# STM32H5F5 register map
File version: 1.0
CPU: CM33 r0p0, little endian, MPU, FPU, 4 interrupt priority bits
Registers are 32-bit, read-write, reset 0x0 unless marked. A register's access mark holds for its fields unless they carry their own. Offsets are from the block's base; [hi:lo] are bit positions; {n}, {i} and the like mark numbered series; 'fields as' and 'values as' point back to an identical list.

## AES — AES register block
Base 0x420C0000
Same registers: SAES 0x420C0C00, AES_S 0x520C0000, SAES_S 0x520C0C00
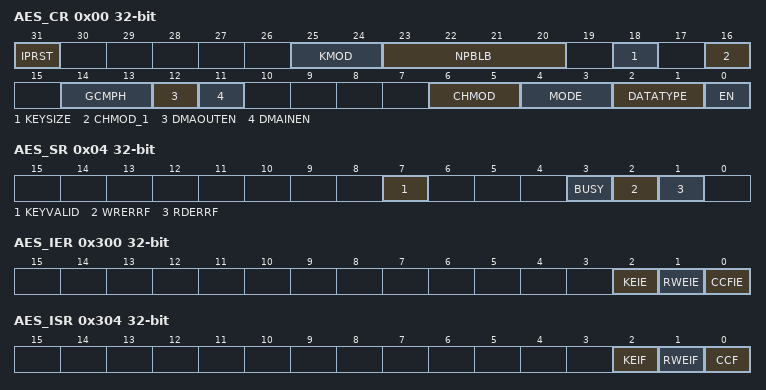
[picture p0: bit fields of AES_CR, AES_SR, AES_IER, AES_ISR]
0x00 AES_CR — AES control register
  [31] IPRST — AES peripheral software reset
  [25:24] KMOD — Key mode selection
    0=Normal key mode; 2=Shared key mode
  [23:20] NPBLB — Number of padding bytes in last block
    0=All bytes are valid (no padding); 1=Padding for the last LSB byte; 15=Padding for the 15 LSB bytes of last block
  [18] KEYSIZE — Key size selection
    0=128-bit; 1=256-bit
  [16] CHMOD_1 — CHMOD[2]
  [14:13] GCMPH — GCM or CCM phase selection
    0=Initialization phase; 1=Header phase; 2=Payload phase; 3=Final phase
  [12] DMAOUTEN — DMA output enable
    0=Disable; 1=Enable
  [11] DMAINEN — DMA input enable
    0=Disable; 1=Enable
  [6:5] CHMOD — CHMOD[1:0]: Chaining mode
    0=Electronic codebook (ECB); 1=Cipher-block chaining (CBC); 2=Counter mode (CTR); 3=Galois counter mode (GCM) and Galois message authentication code (GMAC)
  [4:3] MODE — Operating mode
    0=Encryption; 1=Key derivation (or key preparation), for ECB/CBC decryption only; 2=Decryption
  [2:1] DATATYPE
    0=No swapping (32-bit data); 1=Half-word swapping (16-bit data); 2=Byte swapping (8-bit data); 3=Bit-level swapping
  [0] EN — Enable
    0=Disable; 1=Enable
0x04 AES_SR ro — AES status register
  [7] KEYVALID — Key valid flag
    0=Key not valid; 1=Key valid
  [3] BUSY
    0=Idle; 1=Busy
  [2] WRERRF — Write error flag
    0=No error; 1=Unexpected write to AES_DINR register occurred during computation or data output phase
  [1] RDERRF — Read error flag
    0=No error; 1=Unexpected read to AES_DOUTR register occurred during computation or data input phase
0x08 AES_DINR wo — AES data input register
  [31:0] DIN — Data input
0x0C AES_DOUTR ro — AES data output register
  [31:0] DOUT — Data output
{0x10+4i} AES_KEYR{i} wo (i=0..3) — AES key register {i}
  [31:0] KEY — Cryptographic key, bits [{32i+31}:{32i}]
{0x20+4i} AES_IVR{i} (i=0..3) — AES initialization vector register {i}
  [31:0] IVI — Initialization vector input, bits [{32i+31}:{32i}]
{0x20+4i} AES_KEYR{i} wo (i=4..7) — AES key register {i}
  [31:0] KEY — Cryptographic key, bits [{32i+31}:{32i}]
{0x40+4i} AES_SUSPR{i} (i=0..7) — AES suspend registers
  [31:0] SUSP — Suspend data
0x300 AES_IER — AES interrupt enable register
  [all] fields
    0=Disabled (masked); 1=Enabled (not masked)
  [2] KEIE — Key error interrupt enable
  [1] RWEIE — Read or write error interrupt enable
  [0] CCFIE — Computation complete flag interrupt enable
0x304 AES_ISR ro — AES interrupt status register
  [2] KEIF — Key error interrupt flag
    0=No key error detected; 1=Key information failed to load into key registers
  [1] RWEIF — Read or write error interrupt flag
    0=No read or write error detected; 1=Read or write error detected
  [0] CCF — Computation complete flag
    0=Not completed; 1=Completed
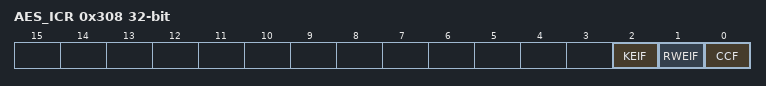
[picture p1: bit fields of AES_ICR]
0x308 AES_ICR wo — AES interrupt clear register
  [2] KEIF — Key error interrupt flag clear
  [1] RWEIF — Read or write error interrupt flag clear
  [0] CCF — Computation complete flag clear

## COMP — COMP register block
Base 0x40004000
Same registers: COMP_S 0x50004000
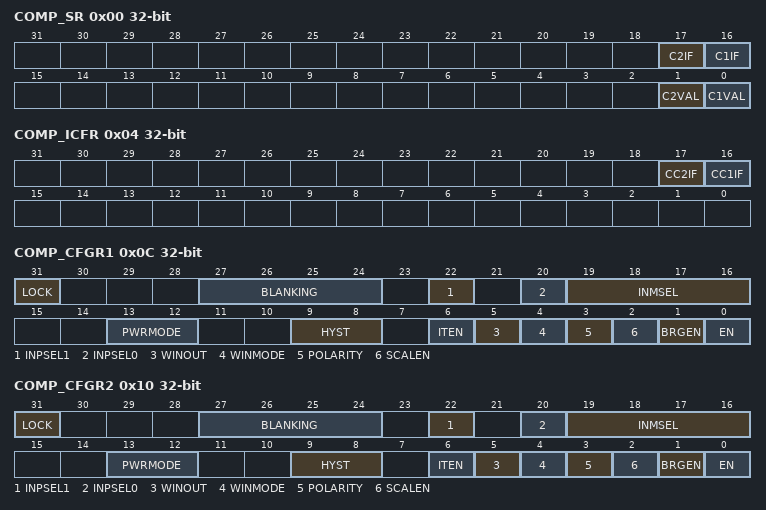
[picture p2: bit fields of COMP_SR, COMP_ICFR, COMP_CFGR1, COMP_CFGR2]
0x00 COMP_SR ro — Comparator status register
  [17] C2IF — COMP2 Channel interrupt flag
  [16] C1IF — COMP1 Channel interrupt flag
  [1] C2VAL — COMP2 Channel output status bit
  [0] C1VAL — COMP1 Channel output status bit
0x04 COMP_ICFR — Comparator interrupt clear flag register
  [17] CC2IF — Clear COMP2 Channel interrupt flag
  [16] CC1IF — Clear COMP1 Channel interrupt flag
0x0C COMP_CFGR1 — Comparator configuration register 1
  [31] LOCK
    0=COMP_CFGR1[31:0] register is read/write; 1=COMP_CFGR1[31:0] register is read-only
  [27:24] BLANKING — COMP1 Channel blanking source selection
  [22] INPSEL1 — COMP1 non-inverting input selection
  [20] INPSEL0 — COMP1 non-inverting input selection
  [19:16] INMSEL — COMP1 Channel inverting input selection
  [13:12] PWRMODE — Power mode of the COMP Channel
    0=High speed / full power; 1=Medium speed / medium power; 2=Medium speed / medium power; 3=Ultra low power / ultra-low-power
  [9:8] HYST — COMP Channel hysteresis selection
    0=No hysteresis; 1=Low hysteresis; 2=Medium hysteresis; 3=High hysteresis
  [6] ITEN — COMP Channel interrupt enable
    0=Interrupt generation disabled for COMP Channel; 1=Interrupt generation enabled for COMP Channel
  [5] WINOUT — COMP1 output selector
    0=COMP1_VALUE; 1=COMP1_VALUE XOR COMP2_VALUE (required for window mode, see Figure331: Window comparators functional block diagram)
  [4] WINMODE — COMP1 non-inverting input selector for window mode
    0=Signal selected with INPSEL[1:0]; 1=COMP2_INP signal of COMP2 (required for window mode, see Figure331: Window comparators functional block diagram)
  [3] POLARITY — COMP Channel polarity selection
    0=COMP Channel output is not inverted; 1=COMP Channel output is inverted
  [2] SCALEN — Voltage scaler enable
    0=Vless thansub>REFINTless than/sub> scaler disabled; 1=Vless thansub>REFINTless than/sub> scaler enabled
  [1] BRGEN — Scaler bridge enable
    0=Scaler resistor bridge disabled; 1=Scaler resistor bridge enabled
  [0] EN — COMP Channel enable
    0=Disable; 1=Enable
0x10 COMP_CFGR2 — Comparator configuration register 2
  [31] LOCK
    0=COMP_CFGR2[31:0] register is read/write; 1=COMP_CFGR2[31:0] register is read-only
  [27:24] BLANKING — COMP2 Channel blanking source selection
  [22] INPSEL1 — COMP2 non-inverting input selection
  [20] INPSEL0 — COMP2 non-inverting input selection
  [19:16] INMSEL — COMP2 Channel inverting input selection
  [13:12] PWRMODE — Power mode of the COMP Channel
    values as COMP_CFGR1.PWRMODE
  [9:8] HYST — COMP Channel hysteresis selection
    values as COMP_CFGR1.HYST
  [6] ITEN — COMP Channel interrupt enable
    values as COMP_CFGR1.ITEN
  [5] WINOUT — COMP2 output selector
    0=COMP2_VALUE; 1=COMP1_VALUE XOR COMP2_VALUE (required for window mode, see Figure331: Window comparators functional block diagram)
  [4] WINMODE — COMP2 non-inverting input selector for window mode
    0=Signal selected with INPSEL[1:0]; 1=COMP1_INP signal of COMP1 (required for window mode, see Figure331: Window comparators functional block diagram)
  [3] POLARITY — COMP Channel polarity selection
    values as COMP_CFGR1.POLARITY
  [2] SCALEN — Voltage scaler enable
    values as COMP_CFGR1.SCALEN
  [1] BRGEN — Scaler bridge enable
    values as COMP_CFGR1.BRGEN
  [0] EN — COMP Channel enable
    0=Disable; 1=Enable
